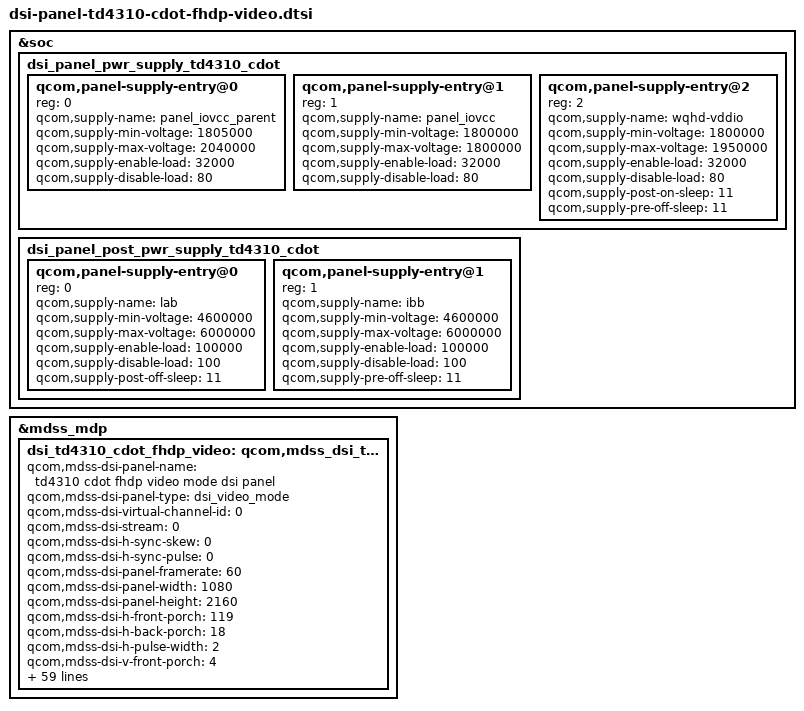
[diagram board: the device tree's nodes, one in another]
/* Copyright (c) 2017, The Linux Foundation. All rights reserved.
 *
 * This program is free software; you can redistribute it and/or modify
 * it under the terms of the GNU General Public License version 2 and
 * only version 2 as published by the Free Software Foundation.
 *
 * This program is distributed in the hope that it will be useful,
 * but WITHOUT ANY WARRANTY; without even the implied warranty of
 * MERCHANTABILITY or FITNESS FOR A PARTICULAR PURPOSE.  See the
 * GNU General Public License for more details.
 */
&soc {
	dsi_panel_pwr_supply_td4310_cdot: dsi_panel_pwr_supply_td4310_cdot {
		#address-cells = <1>;
		#size-cells = <0>;

		qcom,panel-supply-entry@0 {
			reg = <0>;
			qcom,supply-name = "panel_iovcc_parent";
			qcom,supply-min-voltage = <1805000>;
			qcom,supply-max-voltage = <2040000>;
			qcom,supply-enable-load = <32000>;
			qcom,supply-disable-load = <80>;
		};

		qcom,panel-supply-entry@1 {
			reg = <1>;
			qcom,supply-name = "panel_iovcc";
			qcom,supply-min-voltage = <1800000>;
			qcom,supply-max-voltage = <1800000>;
			qcom,supply-enable-load = <32000>;
			qcom,supply-disable-load = <80>;
		};

		qcom,panel-supply-entry@2 {
			reg = <2>;
			qcom,supply-name = "wqhd-vddio";
			qcom,supply-min-voltage = <1800000>;
			qcom,supply-max-voltage = <1950000>;
			qcom,supply-enable-load = <32000>;
			qcom,supply-disable-load = <80>;
			qcom,supply-post-on-sleep = <11>;
			qcom,supply-pre-off-sleep = <11>;
		};
	};

	dsi_panel_post_pwr_supply_td4310_cdot: dsi_panel_post_pwr_supply_td4310_cdot {
		#address-cells = <1>;
		#size-cells = <0>;

		qcom,panel-supply-entry@0 {
			reg = <0>;
			qcom,supply-name = "lab";
			qcom,supply-min-voltage = <4600000>;
			qcom,supply-max-voltage = <6000000>;
			qcom,supply-enable-load = <100000>;
			qcom,supply-disable-load = <100>;
			qcom,supply-post-off-sleep = <11>;
		};

		qcom,panel-supply-entry@1 {
			reg = <1>;
			qcom,supply-name = "ibb";
			qcom,supply-min-voltage = <4600000>;
			qcom,supply-max-voltage = <6000000>;
			qcom,supply-enable-load = <100000>;
			qcom,supply-disable-load = <100>;
			qcom,supply-pre-off-sleep = <11>;
		};
	};
};

&mdss_mdp {
	dsi_td4310_cdot_fhdp_video: qcom,mdss_dsi_td4310_cdot_fhdp_video {
		qcom,mdss-dsi-panel-name = "td4310 cdot fhdp video mode dsi panel";
		qcom,mdss-dsi-panel-type = "dsi_video_mode";
		qcom,mdss-dsi-virtual-channel-id = <0>;
		qcom,mdss-dsi-stream = <0>;
		qcom,mdss-dsi-h-sync-skew = <0>;
		qcom,mdss-dsi-h-sync-pulse = <0>;
		qcom,mdss-dsi-panel-framerate = <60>;
//965MHz
		qcom,mdss-dsi-panel-width = <1080>;
		qcom,mdss-dsi-panel-height = <2160>;
		qcom,mdss-dsi-h-front-porch = <119>;
		qcom,mdss-dsi-h-back-porch = <18>;
		qcom,mdss-dsi-h-pulse-width = <2>;
		qcom,mdss-dsi-v-front-porch = <4>;
		qcom,mdss-dsi-v-back-porch = <33>;
		qcom,mdss-dsi-v-pulse-width = <2>;
		qcom,mdss-dsi-panel-timings = [e6 38 26 00 68 6e 2a
				3c 44 03 04 00];
		qcom,mdss-dsi-panel-timings-phy-v2 = [
			25 1F 09 0A 06 03 04 a0
			25 1F 09 0A 06 03 04 a0
			25 1F 09 0A 06 03 04 a0
			25 1F 09 0A 06 03 04 a0
			25 1D 08 0A 06 03 04 a0];
		qcom,mdss-dsi-t-clk-post = <0x0E>;
		qcom,mdss-dsi-t-clk-pre = <0x33>;

		qcom,mdss-dsi-h-left-border = <0>;
		qcom,mdss-dsi-h-right-border = <0>;
		qcom,mdss-dsi-v-top-border = <0>;
		qcom,mdss-dsi-v-bottom-border = <0>;
		qcom,mdss-dsi-bpp = <24>;
		qcom,mdss-dsi-underflow-color = <0xff>;
		qcom,mdss-dsi-border-color = <0>;

		qcom,mdss-dsi-traffic-mode = "burst_mode";
		qcom,mdss-dsi-bllp-eof-power-mode;
		qcom,mdss-dsi-bllp-power-mode;
		qcom,mdss-dsi-lane-0-state;
		qcom,mdss-dsi-lane-1-state;
		qcom,mdss-dsi-lane-2-state;
		qcom,mdss-dsi-lane-3-state;

		qcom,mdss-dsi-dma-trigger = "trigger_sw";
		qcom,mdss-dsi-mdp-trigger = "none";
		qcom,mdss-dsi-on-command = [
			//cabc 21KHz
			29 01 00 00 00 00 02 B0 00
			29 01 00 00 00 00 02 D6 01
			29 01 00 00 00 00 1A CE 5D 40 49 53 59 5E 63 68 6E 74 7E 8A 98 A8 BB D0 FF 03 00 04 04 42 00 69 5A
			39 01 00 00 00 00 02 51 ff
			39 01 00 00 00 00 02 53 24
			39 01 00 00 00 00 02 55 02
			05 01 00 00 46 00 02 11 00
			05 01 00 00 14 00 02 29 00
			];
		qcom,mdss-dsi-off-command = [05 01 00 00 14 00 02 28 00
				 05 01 00 00 78 00 02 10 00];
		qcom,mdss-dsi-on-command-state = "dsi_lp_mode";
		qcom,mdss-dsi-off-command-state = "dsi_lp_mode";

		qcom,esd-check-enabled;
		qcom,mdss-dsi-panel-status-check-mode = "reg_read";
		qcom,mdss-dsi-panel-status-command = [06 01 00 01 00 00 01 0a];
		qcom,mdss-dsi-panel-status-command-state = "dsi_hs_mode";
		qcom,mdss-dsi-panel-status-value = <0x1C>;
		qcom,mdss-dsi-panel-on-check-value = <0x1C>;
		qcom,mdss-dsi-panel-status-read-length = <1>;
		qcom,mdss-dsi-panel-max-error-count = <3>;

		qcom,mdss-dsi-lp11-init;
		qcom,mdss-dsi-lp11-deinit;
		qcom,mdss-dsi-init-delay-us = <10000>;
		qcom,suspend-ulps-enabled;
		qcom,mdss-dsi-reset-sequence = <1 2>, <0 13>, <1 55>;
		qcom,mdss-dsi-tx-eot-append;
		qcom,mdss-dsi-post-init-delay = <1>;
		qcom,mdss-dsi-bl-pmic-control-type = "bl_ctrl_wled";
		qcom,mdss-dsi-bl-min-level = <45>;
		qcom,mdss-dsi-bl-default-level = <850>;
		qcom,mdss-dsi-bl-max-level = <4095>;
		qcom,mdss-pan-physical-width-dimension = <68>;
		qcom,mdss-pan-physical-height-dimension = <136>;
		qcom,panel-supply-entries = <&dsi_panel_pwr_supply_td4310_cdot>;
		qcom,panel-post-supply-entries = <&dsi_panel_post_pwr_supply_td4310_cdot>;
	};
};
